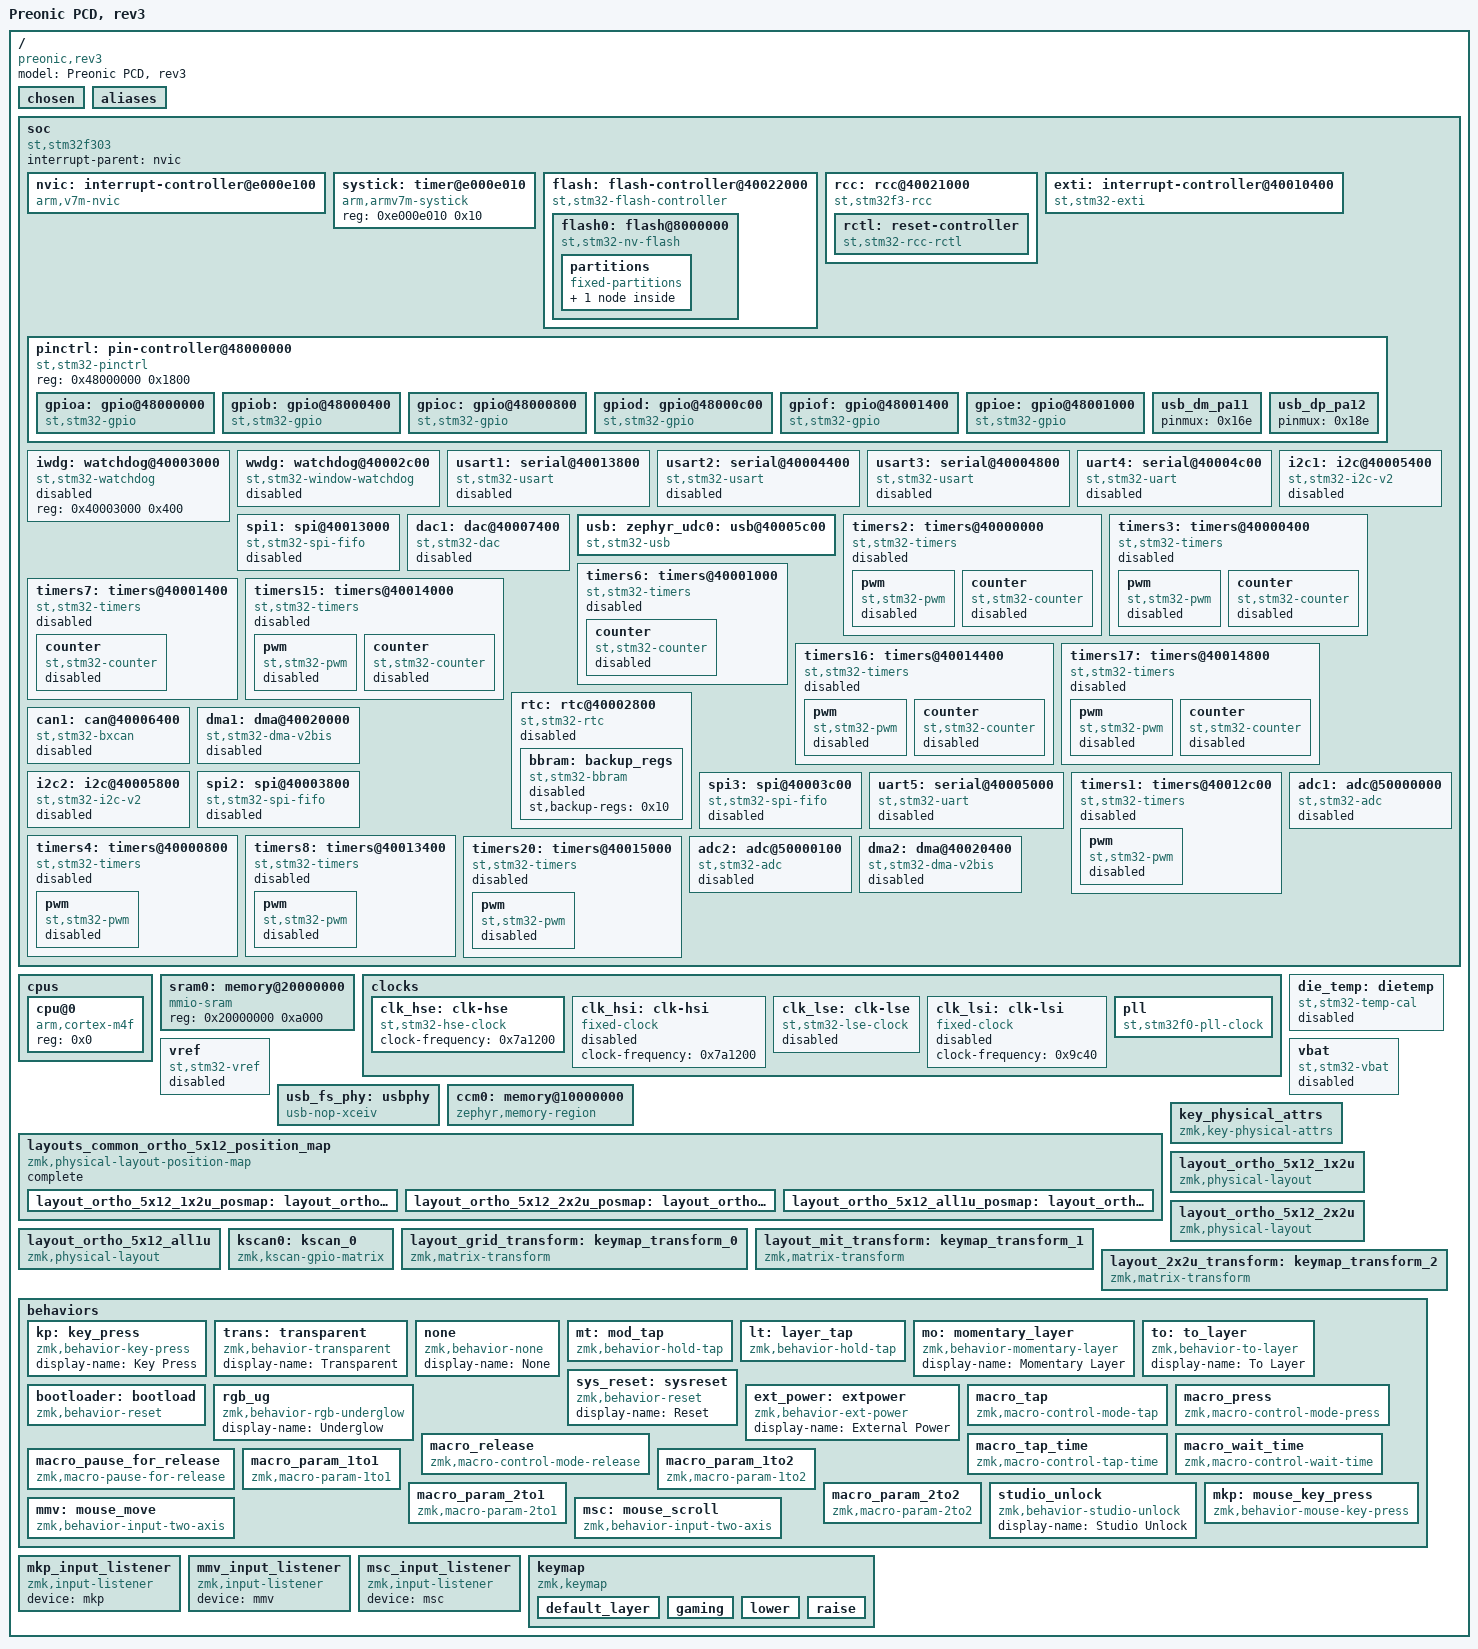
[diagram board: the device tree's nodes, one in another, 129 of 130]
/dts-v1/;

/ {
	#address-cells = < 0x1 >;
	#size-cells = < 0x1 >;
	model = "Preonic PCD, rev3";
	compatible = "preonic,rev3", "st,stm32f303";
	chosen {
		zephyr,flash-controller = &flash;
		zephyr,sram = &sram0;
		zephyr,flash = &flash0;
		zmk,kscan = &kscan0;
		zmk,physical-layout = &layout_ortho_5x12_all1u;
	};
	aliases {
	};
	soc {
		#address-cells = < 0x1 >;
		#size-cells = < 0x1 >;
		compatible = "st,stm32f303", "st,stm32f3", "simple-bus";
		interrupt-parent = < &nvic >;
		ranges;
		nvic: interrupt-controller@e000e100 {
			#address-cells = < 0x1 >;
			compatible = "arm,v7m-nvic";
			reg = < 0xe000e100 0xc00 >;
			interrupt-controller;
			#interrupt-cells = < 0x2 >;
			arm,num-irq-priority-bits = < 0x4 >;
			phandle = < 0x1 >;
		};
		systick: timer@e000e010 {
			compatible = "arm,armv7m-systick";
			reg = < 0xe000e010 0x10 >;
		};
		flash: flash-controller@40022000 {
			compatible = "st,stm32-flash-controller", "st,stm32f1-flash-controller";
			reg = < 0x40022000 0x400 >;
			interrupts = < 0x4 0x0 >;
			clocks = < &rcc 0x14 0x10 >;
			#address-cells = < 0x1 >;
			#size-cells = < 0x1 >;
			flash0: flash@8000000 {
				compatible = "st,stm32-nv-flash", "soc-nv-flash";
				write-block-size = < 0x2 >;
				erase-block-size = < 0x800 >;
				max-erase-time = < 0x28 >;
				reg = < 0x8000000 0x40000 >;
				partitions {
					compatible = "fixed-partitions";
					#address-cells = < 0x1 >;
					#size-cells = < 0x1 >;
					storage_partition: partition@3e800 {
						reg = < 0x3e800 0x1800 >;
					};
				};
			};
		};
		rcc: rcc@40021000 {
			compatible = "st,stm32f3-rcc";
			#clock-cells = < 0x2 >;
			reg = < 0x40021000 0x400 >;
			clocks = < &pll >;
			clock-frequency = < 0x44aa200 >;
			ahb-prescaler = < 0x1 >;
			apb1-prescaler = < 0x2 >;
			apb2-prescaler = < 0x1 >;
			phandle = < 0x2 >;
			rctl: reset-controller {
				compatible = "st,stm32-rcc-rctl";
				#reset-cells = < 0x1 >;
				phandle = < 0x4 >;
			};
		};
		exti: interrupt-controller@40010400 {
			compatible = "st,stm32-exti";
			interrupt-controller;
			#interrupt-cells = < 0x1 >;
			#address-cells = < 0x1 >;
			reg = < 0x40010400 0x400 >;
			num-lines = < 0x10 >;
			interrupts = < 0x6 0x0 >, < 0x7 0x0 >, < 0x8 0x0 >, < 0x9 0x0 >, < 0xa 0x0 >, < 0x17 0x0 >, < 0x28 0x0 >;
			interrupt-names = "line0", "line1", "line2", "line3", "line4", "line5-9", "line10-15";
			line-ranges = < 0x0 0x1 >, < 0x1 0x1 >, < 0x2 0x1 >, < 0x3 0x1 >, < 0x4 0x1 >, < 0x5 0x5 >, < 0xa 0x6 >;
		};
		pinctrl: pin-controller@48000000 {
			compatible = "st,stm32-pinctrl";
			#address-cells = < 0x1 >;
			#size-cells = < 0x1 >;
			reg = < 0x48000000 0x1800 >;
			gpioa: gpio@48000000 {
				compatible = "st,stm32-gpio";
				gpio-controller;
				#gpio-cells = < 0x2 >;
				reg = < 0x48000000 0x400 >;
				clocks = < &rcc 0x14 0x20000 >;
				phandle = < 0x11 >;
			};
			gpiob: gpio@48000400 {
				compatible = "st,stm32-gpio";
				gpio-controller;
				#gpio-cells = < 0x2 >;
				reg = < 0x48000400 0x400 >;
				clocks = < &rcc 0x14 0x40000 >;
				phandle = < 0x12 >;
			};
			gpioc: gpio@48000800 {
				compatible = "st,stm32-gpio";
				gpio-controller;
				#gpio-cells = < 0x2 >;
				reg = < 0x48000800 0x400 >;
				clocks = < &rcc 0x14 0x80000 >;
				phandle = < 0x13 >;
			};
			gpiod: gpio@48000c00 {
				compatible = "st,stm32-gpio";
				gpio-controller;
				#gpio-cells = < 0x2 >;
				reg = < 0x48000c00 0x400 >;
				clocks = < &rcc 0x14 0x100000 >;
			};
			gpiof: gpio@48001400 {
				compatible = "st,stm32-gpio";
				gpio-controller;
				#gpio-cells = < 0x2 >;
				reg = < 0x48001400 0x400 >;
				clocks = < &rcc 0x14 0x400000 >;
			};
			gpioe: gpio@48001000 {
				compatible = "st,stm32-gpio";
				gpio-controller;
				#gpio-cells = < 0x2 >;
				reg = < 0x48001000 0x400 >;
				clocks = < &rcc 0x14 0x200000 >;
			};
			usb_dm_pa11: usb_dm_pa11 {
				pinmux = < 0x16e >;
				phandle = < 0x6 >;
			};
			usb_dp_pa12: usb_dp_pa12 {
				pinmux = < 0x18e >;
				phandle = < 0x7 >;
			};
		};
		iwdg: watchdog@40003000 {
			compatible = "st,stm32-watchdog";
			reg = < 0x40003000 0x400 >;
			status = "disabled";
		};
		wwdg: watchdog@40002c00 {
			compatible = "st,stm32-window-watchdog";
			reg = < 0x40002c00 0x400 >;
			clocks = < &rcc 0x1c 0x800 >;
			interrupts = < 0x0 0x7 >;
			status = "disabled";
		};
		usart1: serial@40013800 {
			compatible = "st,stm32-usart", "st,stm32-uart";
			reg = < 0x40013800 0x400 >;
			clocks = < &rcc 0x18 0x4000 >;
			resets = < &rctl 0x18e >;
			interrupts = < 0x25 0x0 >;
			status = "disabled";
		};
		usart2: serial@40004400 {
			compatible = "st,stm32-usart", "st,stm32-uart";
			reg = < 0x40004400 0x400 >;
			clocks = < &rcc 0x1c 0x20000 >;
			resets = < &rctl 0x211 >;
			interrupts = < 0x26 0x0 >;
			status = "disabled";
		};
		usart3: serial@40004800 {
			compatible = "st,stm32-usart", "st,stm32-uart";
			reg = < 0x40004800 0x400 >;
			clocks = < &rcc 0x1c 0x40000 >;
			resets = < &rctl 0x212 >;
			interrupts = < 0x27 0x0 >;
			status = "disabled";
		};
		uart4: serial@40004c00 {
			compatible = "st,stm32-uart";
			reg = < 0x40004c00 0x400 >;
			clocks = < &rcc 0x1c 0x80000 >;
			resets = < &rctl 0x213 >;
			interrupts = < 0x34 0x0 >;
			status = "disabled";
		};
		i2c1: i2c@40005400 {
			compatible = "st,stm32-i2c-v2";
			clock-frequency = < 0x186a0 >;
			#address-cells = < 0x1 >;
			#size-cells = < 0x0 >;
			reg = < 0x40005400 0x400 >;
			clocks = < &rcc 0x1c 0x200000 >, < &rcc 0x4 0x12430 >;
			interrupts = < 0x1f 0x0 >, < 0x20 0x0 >;
			interrupt-names = "event", "error";
			status = "disabled";
		};
		spi1: spi@40013000 {
			compatible = "st,stm32-spi-fifo", "st,stm32-spi";
			#address-cells = < 0x1 >;
			#size-cells = < 0x0 >;
			reg = < 0x40013000 0x400 >;
			clocks = < &rcc 0x18 0x1000 >;
			interrupts = < 0x23 0x5 >;
			status = "disabled";
		};
		dac1: dac@40007400 {
			compatible = "st,stm32-dac";
			reg = < 0x40007400 0x400 >;
			clocks = < &rcc 0x1c 0x20000000 >;
			status = "disabled";
			#io-channel-cells = < 0x1 >;
		};
		usb: zephyr_udc0: usb@40005c00 {
			compatible = "st,stm32-usb";
			reg = < 0x40005c00 0x400 >;
			interrupts = < 0x4b 0x0 >;
			interrupt-names = "usb";
			num-bidir-endpoints = < 0x8 >;
			ram-size = < 0x200 >;
			phys = < &usb_fs_phy >;
			clocks = < &rcc 0x1c 0x800000 >;
			status = "okay";
			pinctrl-0 = < &usb_dm_pa11 &usb_dp_pa12 >;
			pinctrl-names = "default";
		};
		timers2: timers@40000000 {
			compatible = "st,stm32-timers";
			reg = < 0x40000000 0x400 >;
			clocks = < &rcc 0x1c 0x1 >;
			resets = < &rctl 0x200 >;
			interrupts = < 0x1c 0x0 >;
			interrupt-names = "global";
			st,prescaler = < 0x0 >;
			status = "disabled";
			pwm {
				compatible = "st,stm32-pwm";
				status = "disabled";
				#pwm-cells = < 0x3 >;
			};
			counter {
				compatible = "st,stm32-counter";
				status = "disabled";
			};
		};
		timers3: timers@40000400 {
			compatible = "st,stm32-timers";
			reg = < 0x40000400 0x400 >;
			clocks = < &rcc 0x1c 0x2 >;
			resets = < &rctl 0x201 >;
			interrupts = < 0x1d 0x0 >;
			interrupt-names = "global";
			st,prescaler = < 0x0 >;
			status = "disabled";
			pwm {
				compatible = "st,stm32-pwm";
				status = "disabled";
				#pwm-cells = < 0x3 >;
			};
			counter {
				compatible = "st,stm32-counter";
				status = "disabled";
			};
		};
		timers6: timers@40001000 {
			compatible = "st,stm32-timers";
			reg = < 0x40001000 0x400 >;
			clocks = < &rcc 0x1c 0x10 >;
			resets = < &rctl 0x204 >;
			interrupts = < 0x36 0x0 >;
			interrupt-names = "global";
			st,prescaler = < 0x0 >;
			status = "disabled";
			counter {
				compatible = "st,stm32-counter";
				status = "disabled";
			};
		};
		timers7: timers@40001400 {
			compatible = "st,stm32-timers";
			reg = < 0x40001400 0x400 >;
			clocks = < &rcc 0x1c 0x20 >;
			resets = < &rctl 0x205 >;
			interrupts = < 0x37 0x0 >;
			interrupt-names = "global";
			st,prescaler = < 0x0 >;
			status = "disabled";
			counter {
				compatible = "st,stm32-counter";
				status = "disabled";
			};
		};
		timers15: timers@40014000 {
			compatible = "st,stm32-timers";
			reg = < 0x40014000 0x400 >;
			clocks = < &rcc 0x18 0x10000 >;
			resets = < &rctl 0x190 >;
			interrupts = < 0x18 0x0 >;
			interrupt-names = "global";
			st,prescaler = < 0x0 >;
			status = "disabled";
			pwm {
				compatible = "st,stm32-pwm";
				status = "disabled";
				#pwm-cells = < 0x3 >;
			};
			counter {
				compatible = "st,stm32-counter";
				status = "disabled";
			};
		};
		timers16: timers@40014400 {
			compatible = "st,stm32-timers";
			reg = < 0x40014400 0x400 >;
			clocks = < &rcc 0x18 0x20000 >;
			resets = < &rctl 0x191 >;
			interrupts = < 0x19 0x0 >;
			interrupt-names = "global";
			st,prescaler = < 0x0 >;
			status = "disabled";
			pwm {
				compatible = "st,stm32-pwm";
				status = "disabled";
				#pwm-cells = < 0x3 >;
			};
			counter {
				compatible = "st,stm32-counter";
				status = "disabled";
			};
		};
		timers17: timers@40014800 {
			compatible = "st,stm32-timers";
			reg = < 0x40014800 0x400 >;
			clocks = < &rcc 0x18 0x40000 >;
			resets = < &rctl 0x192 >;
			interrupts = < 0x1a 0x0 >;
			interrupt-names = "global";
			st,prescaler = < 0x0 >;
			status = "disabled";
			pwm {
				compatible = "st,stm32-pwm";
				status = "disabled";
				#pwm-cells = < 0x3 >;
			};
			counter {
				compatible = "st,stm32-counter";
				status = "disabled";
			};
		};
		rtc: rtc@40002800 {
			compatible = "st,stm32-rtc";
			reg = < 0x40002800 0x400 >;
			clocks = < &rcc 0x1c 0x10000000 >;
			interrupts = < 0x29 0x0 >;
			prescaler = < 0x8000 >;
			status = "disabled";
			bbram: backup_regs {
				compatible = "st,stm32-bbram";
				st,backup-regs = < 0x10 >;
				status = "disabled";
			};
		};
		can1: can@40006400 {
			compatible = "st,stm32-bxcan";
			reg = < 0x40006400 0x400 >;
			interrupts = < 0x13 0x0 >, < 0x14 0x0 >, < 0x15 0x0 >, < 0x16 0x0 >;
			interrupt-names = "TX", "RX0", "RX1", "SCE";
			clocks = < &rcc 0x1c 0x2000000 >;
			status = "disabled";
			sample-point = < 0x36b >;
		};
		dma1: dma@40020000 {
			compatible = "st,stm32-dma-v2bis";
			#dma-cells = < 0x2 >;
			reg = < 0x40020000 0x400 >;
			clocks = < &rcc 0x14 0x1 >;
			interrupts = < 0xb 0x0 0xc 0x0 0xd 0x0 0xe 0x0 0xf 0x0 0x10 0x0 0x11 0x0 >;
			status = "disabled";
		};
		i2c2: i2c@40005800 {
			compatible = "st,stm32-i2c-v2";
			clock-frequency = < 0x186a0 >;
			#address-cells = < 0x1 >;
			#size-cells = < 0x0 >;
			reg = < 0x40005800 0x400 >;
			clocks = < &rcc 0x1c 0x400000 >, < &rcc 0x4 0x12530 >;
			interrupts = < 0x21 0x0 >, < 0x22 0x0 >;
			interrupt-names = "event", "error";
			status = "disabled";
		};
		spi2: spi@40003800 {
			compatible = "st,stm32-spi-fifo", "st,stm32-spi";
			#address-cells = < 0x1 >;
			#size-cells = < 0x0 >;
			reg = < 0x40003800 0x400 >;
			clocks = < &rcc 0x1c 0x4000 >;
			interrupts = < 0x24 0x5 >;
			status = "disabled";
		};
		spi3: spi@40003c00 {
			compatible = "st,stm32-spi-fifo", "st,stm32-spi";
			#address-cells = < 0x1 >;
			#size-cells = < 0x0 >;
			reg = < 0x40003c00 0x400 >;
			clocks = < &rcc 0x1c 0x8000 >;
			interrupts = < 0x33 0x5 >;
			status = "disabled";
		};
		uart5: serial@40005000 {
			compatible = "st,stm32-uart";
			reg = < 0x40005000 0x400 >;
			clocks = < &rcc 0x1c 0x100000 >;
			resets = < &rctl 0x214 >;
			interrupts = < 0x35 0x0 >;
			status = "disabled";
		};
		timers1: timers@40012c00 {
			compatible = "st,stm32-timers";
			reg = < 0x40012c00 0x400 >;
			clocks = < &rcc 0x18 0x800 >;
			resets = < &rctl 0x18b >;
			interrupts = < 0x18 0x0 >, < 0x19 0x0 >, < 0x1a 0x0 >, < 0x1b 0x0 >;
			interrupt-names = "brk", "up", "trgcom", "cc";
			st,prescaler = < 0x0 >;
			status = "disabled";
			pwm {
				compatible = "st,stm32-pwm";
				status = "disabled";
				#pwm-cells = < 0x3 >;
			};
		};
		timers4: timers@40000800 {
			compatible = "st,stm32-timers";
			reg = < 0x40000800 0x400 >;
			clocks = < &rcc 0x1c 0x4 >;
			resets = < &rctl 0x202 >;
			interrupts = < 0x1e 0x0 >;
			interrupt-names = "global";
			st,prescaler = < 0x0 >;
			status = "disabled";
			pwm {
				compatible = "st,stm32-pwm";
				status = "disabled";
				#pwm-cells = < 0x3 >;
			};
		};
		timers8: timers@40013400 {
			compatible = "st,stm32-timers";
			reg = < 0x40013400 0x400 >;
			clocks = < &rcc 0x18 0x2000 >;
			resets = < &rctl 0x18d >;
			interrupts = < 0x2b 0x0 >, < 0x2c 0x0 >, < 0x2d 0x0 >, < 0x2e 0x0 >;
			interrupt-names = "brk", "up", "trgcom", "cc";
			st,prescaler = < 0x0 >;
			status = "disabled";
			pwm {
				compatible = "st,stm32-pwm";
				status = "disabled";
				#pwm-cells = < 0x3 >;
			};
		};
		timers20: timers@40015000 {
			compatible = "st,stm32-timers";
			reg = < 0x40015000 0x400 >;
			clocks = < &rcc 0x18 0x100000 >;
			resets = < &rctl 0x194 >;
			interrupts = < 0x4d 0x0 >, < 0x4e 0x0 >, < 0x4f 0x0 >, < 0x50 0x0 >;
			interrupt-names = "brk", "up", "trgcom", "cc";
			st,prescaler = < 0x0 >;
			status = "disabled";
			pwm {
				compatible = "st,stm32-pwm";
				status = "disabled";
				#pwm-cells = < 0x3 >;
			};
		};
		adc1: adc@50000000 {
			compatible = "st,stm32-adc";
			reg = < 0x50000000 0x400 >;
			clocks = < &rcc 0x14 0x10000000 >;
			interrupts = < 0x12 0x0 >;
			status = "disabled";
			vref-mv = < 0xbb8 >;
			#io-channel-cells = < 0x1 >;
			resolutions = < 0x60630c 0x51630c 0x42630c 0x33630c >;
			sampling-times = < 0x2 0x3 0x5 0x8 0x14 0x3e 0xb6 0x25a >;
			st,adc-sequencer = < 0x1 >;
			phandle = < 0x9 >;
		};
		adc2: adc@50000100 {
			compatible = "st,stm32-adc";
			reg = < 0x50000100 0x4c >;
			clocks = < &rcc 0x14 0x10000000 >;
			interrupts = < 0x12 0x0 >;
			status = "disabled";
			vref-mv = < 0xbb8 >;
			#io-channel-cells = < 0x1 >;
			resolutions = < 0x60630c 0x51630c 0x42630c 0x33630c >;
			sampling-times = < 0x2 0x3 0x5 0x8 0x14 0x3e 0xb6 0x25a >;
			st,adc-sequencer = < 0x1 >;
		};
		dma2: dma@40020400 {
			compatible = "st,stm32-dma-v2bis";
			#dma-cells = < 0x2 >;
			reg = < 0x40020400 0x400 >;
			clocks = < &rcc 0x14 0x2 >;
			interrupts = < 0x38 0x0 0x39 0x0 0x3a 0x0 0x3b 0x0 0x3c 0x0 >;
			status = "disabled";
		};
	};
	cpus {
		#address-cells = < 0x1 >;
		#size-cells = < 0x0 >;
		cpu@0 {
			device_type = "cpu";
			compatible = "arm,cortex-m4f";
			reg = < 0x0 >;
		};
	};
	sram0: memory@20000000 {
		compatible = "mmio-sram";
		reg = < 0x20000000 0xa000 >;
	};
	clocks {
		clk_hse: clk-hse {
			#clock-cells = < 0x0 >;
			compatible = "st,stm32-hse-clock";
			status = "okay";
			clock-frequency = < 0x7a1200 >;
			phandle = < 0x8 >;
		};
		clk_hsi: clk-hsi {
			#clock-cells = < 0x0 >;
			compatible = "fixed-clock";
			clock-frequency = < 0x7a1200 >;
			status = "disabled";
		};
		clk_lse: clk-lse {
			#clock-cells = < 0x0 >;
			compatible = "st,stm32-lse-clock";
			clock-frequency = < 0x8000 >;
			driving-capability = < 0x0 >;
			status = "disabled";
		};
		clk_lsi: clk-lsi {
			#clock-cells = < 0x0 >;
			compatible = "fixed-clock";
			clock-frequency = < 0x9c40 >;
			status = "disabled";
		};
		pll: pll {
			#clock-cells = < 0x0 >;
			compatible = "st,stm32f0-pll-clock";
			status = "okay";
			prediv = < 0x1 >;
			mul = < 0x9 >;
			clocks = < &clk_hse >;
			phandle = < 0x3 >;
		};
	};
	die_temp: dietemp {
		compatible = "st,stm32-temp-cal";
		ts-cal1-addr = < 0x1ffff7b8 >;
		ts-cal2-addr = < 0x1ffff7c2 >;
		ts-cal1-temp = < 0x1e >;
		ts-cal2-temp = < 0x6e >;
		ts-cal-vrefanalog = < 0xce4 >;
		io-channels = < &adc1 0x10 >;
		status = "disabled";
	};
	vref: vref {
		compatible = "st,stm32-vref";
		vrefint-cal-addr = < 0x1ffff7ba >;
		vrefint-cal-mv = < 0xce4 >;
		io-channels = < &adc1 0x12 >;
		status = "disabled";
	};
	vbat: vbat {
		compatible = "st,stm32-vbat";
		ratio = < 0x2 >;
		io-channels = < &adc1 0x11 >;
		status = "disabled";
	};
	usb_fs_phy: usbphy {
		compatible = "usb-nop-xceiv";
		#phy-cells = < 0x0 >;
		phandle = < 0x5 >;
	};
	ccm0: memory@10000000 {
		compatible = "zephyr,memory-region", "st,stm32-ccm";
		reg = < 0x10000000 0x2000 >;
		zephyr,memory-region = "CCM";
	};
	layouts_common_ortho_5x12_position_map: layouts_common_ortho_5x12_position_map {
		compatible = "zmk,physical-layout-position-map";
		complete;
		layout_ortho_5x12_1x2u_posmap: layout_ortho_5x12_1x2u {
			physical-layout = < &layout_ortho_5x12_1x2u >;
			positions = < 0x0 0x1 0x2 0x3 0x4 0x5 0x6 0x7 0x8 0x9 0xa 0xb >, < 0xc 0xd 0xe 0xf 0x10 0x11 0x12 0x13 0x14 0x15 0x16 0x17 >, < 0x18 0x19 0x1a 0x1b 0x1c 0x1d 0x1e 0x1f 0x20 0x21 0x22 0x23 >, < 0x24 0x25 0x26 0x27 0x28 0x29 0x2a 0x2b 0x2c 0x2d 0x2e 0x2f >, < 0x30 0x31 0x32 0x33 0x34 0x35 0x3b 0x36 0x37 0x38 0x39 0x3a >;
		};
		layout_ortho_5x12_2x2u_posmap: layout_ortho_5x12_2x2u {
			physical-layout = < &layout_ortho_5x12_2x2u >;
			positions = < 0x0 0x1 0x2 0x3 0x4 0x5 0x6 0x7 0x8 0x9 0xa 0xb >, < 0xc 0xd 0xe 0xf 0x10 0x11 0x12 0x13 0x14 0x15 0x16 0x17 >, < 0x18 0x19 0x1a 0x1b 0x1c 0x1d 0x1e 0x1f 0x20 0x21 0x22 0x23 >, < 0x24 0x25 0x26 0x27 0x28 0x29 0x2a 0x2b 0x2c 0x2d 0x2e 0x2f >, < 0x30 0x31 0x32 0x33 0x34 0x3a 0x3b 0x35 0x36 0x37 0x38 0x39 >;
		};
		layout_ortho_5x12_all1u_posmap: layout_ortho_5x12_all1u {
			physical-layout = < &layout_ortho_5x12_all1u >;
			positions = < 0x0 0x1 0x2 0x3 0x4 0x5 0x6 0x7 0x8 0x9 0xa 0xb >, < 0xc 0xd 0xe 0xf 0x10 0x11 0x12 0x13 0x14 0x15 0x16 0x17 >, < 0x18 0x19 0x1a 0x1b 0x1c 0x1d 0x1e 0x1f 0x20 0x21 0x22 0x23 >, < 0x24 0x25 0x26 0x27 0x28 0x29 0x2a 0x2b 0x2c 0x2d 0x2e 0x2f >, < 0x30 0x31 0x32 0x33 0x34 0x35 0x36 0x37 0x38 0x39 0x3a 0x3b >;
		};
	};
	key_physical_attrs: key_physical_attrs {
		compatible = "zmk,key-physical-attrs";
		#key-cells = < 0x7 >;
		phandle = < 0xd >;
	};
	layout_ortho_5x12_1x2u: layout_ortho_5x12_1x2u {
		compatible = "zmk,physical-layout";
		display-name = "50% 1x2U Space";
		keys = < &key_physical_attrs 0x64 0x64 0x0 0x0 0x0 0x0 0x0 >, < &key_physical_attrs 0x64 0x64 0x64 0x0 0x0 0x0 0x0 >, < &key_physical_attrs 0x64 0x64 0xc8 0x0 0x0 0x0 0x0 >, < &key_physical_attrs 0x64 0x64 0x12c 0x0 0x0 0x0 0x0 >, < &key_physical_attrs 0x64 0x64 0x190 0x0 0x0 0x0 0x0 >, < &key_physical_attrs 0x64 0x64 0x1f4 0x0 0x0 0x0 0x0 >, < &key_physical_attrs 0x64 0x64 0x258 0x0 0x0 0x0 0x0 >, < &key_physical_attrs 0x64 0x64 0x2bc 0x0 0x0 0x0 0x0 >, < &key_physical_attrs 0x64 0x64 0x320 0x0 0x0 0x0 0x0 >, < &key_physical_attrs 0x64 0x64 0x384 0x0 0x0 0x0 0x0 >, < &key_physical_attrs 0x64 0x64 0x3e8 0x0 0x0 0x0 0x0 >, < &key_physical_attrs 0x64 0x64 0x44c 0x0 0x0 0x0 0x0 >, < &key_physical_attrs 0x64 0x64 0x0 0x64 0x0 0x0 0x0 >, < &key_physical_attrs 0x64 0x64 0x64 0x64 0x0 0x0 0x0 >, < &key_physical_attrs 0x64 0x64 0xc8 0x64 0x0 0x0 0x0 >, < &key_physical_attrs 0x64 0x64 0x12c 0x64 0x0 0x0 0x0 >, < &key_physical_attrs 0x64 0x64 0x190 0x64 0x0 0x0 0x0 >, < &key_physical_attrs 0x64 0x64 0x1f4 0x64 0x0 0x0 0x0 >, < &key_physical_attrs 0x64 0x64 0x258 0x64 0x0 0x0 0x0 >, < &key_physical_attrs 0x64 0x64 0x2bc 0x64 0x0 0x0 0x0 >, < &key_physical_attrs 0x64 0x64 0x320 0x64 0x0 0x0 0x0 >, < &key_physical_attrs 0x64 0x64 0x384 0x64 0x0 0x0 0x0 >, < &key_physical_attrs 0x64 0x64 0x3e8 0x64 0x0 0x0 0x0 >, < &key_physical_attrs 0x64 0x64 0x44c 0x64 0x0 0x0 0x0 >, < &key_physical_attrs 0x64 0x64 0x0 0xc8 0x0 0x0 0x0 >, < &key_physical_attrs 0x64 0x64 0x64 0xc8 0x0 0x0 0x0 >, < &key_physical_attrs 0x64 0x64 0xc8 0xc8 0x0 0x0 0x0 >, < &key_physical_attrs 0x64 0x64 0x12c 0xc8 0x0 0x0 0x0 >, < &key_physical_attrs 0x64 0x64 0x190 0xc8 0x0 0x0 0x0 >, < &key_physical_attrs 0x64 0x64 0x1f4 0xc8 0x0 0x0 0x0 >, < &key_physical_attrs 0x64 0x64 0x258 0xc8 0x0 0x0 0x0 >, < &key_physical_attrs 0x64 0x64 0x2bc 0xc8 0x0 0x0 0x0 >, < &key_physical_attrs 0x64 0x64 0x320 0xc8 0x0 0x0 0x0 >, < &key_physical_attrs 0x64 0x64 0x384 0xc8 0x0 0x0 0x0 >, < &key_physical_attrs 0x64 0x64 0x3e8 0xc8 0x0 0x0 0x0 >, < &key_physical_attrs 0x64 0x64 0x44c 0xc8 0x0 0x0 0x0 >, < &key_physical_attrs 0x64 0x64 0x0 0x12c 0x0 0x0 0x0 >, < &key_physical_attrs 0x64 0x64 0x64 0x12c 0x0 0x0 0x0 >, < &key_physical_attrs 0x64 0x64 0xc8 0x12c 0x0 0x0 0x0 >, < &key_physical_attrs 0x64 0x64 0x12c 0x12c 0x0 0x0 0x0 >, < &key_physical_attrs 0x64 0x64 0x190 0x12c 0x0 0x0 0x0 >, < &key_physical_attrs 0x64 0x64 0x1f4 0x12c 0x0 0x0 0x0 >, < &key_physical_attrs 0x64 0x64 0x258 0x12c 0x0 0x0 0x0 >, < &key_physical_attrs 0x64 0x64 0x2bc 0x12c 0x0 0x0 0x0 >, < &key_physical_attrs 0x64 0x64 0x320 0x12c 0x0 0x0 0x0 >, < &key_physical_attrs 0x64 0x64 0x384 0x12c 0x0 0x0 0x0 >, < &key_physical_attrs 0x64 0x64 0x3e8 0x12c 0x0 0x0 0x0 >, < &key_physical_attrs 0x64 0x64 0x44c 0x12c 0x0 0x0 0x0 >, < &key_physical_attrs 0x64 0x64 0x0 0x190 0x0 0x0 0x0 >, < &key_physical_attrs 0x64 0x64 0x64 0x190 0x0 0x0 0x0 >, < &key_physical_attrs 0x64 0x64 0xc8 0x190 0x0 0x0 0x0 >, < &key_physical_attrs 0x64 0x64 0x12c 0x190 0x0 0x0 0x0 >, < &key_physical_attrs 0x64 0x64 0x190 0x190 0x0 0x0 0x0 >, < &key_physical_attrs 0xc8 0x64 0x1f4 0x190 0x0 0x0 0x0 >, < &key_physical_attrs 0x64 0x64 0x2bc 0x190 0x0 0x0 0x0 >, < &key_physical_attrs 0x64 0x64 0x320 0x190 0x0 0x0 0x0 >, < &key_physical_attrs 0x64 0x64 0x384 0x190 0x0 0x0 0x0 >, < &key_physical_attrs 0x64 0x64 0x3e8 0x190 0x0 0x0 0x0 >, < &key_physical_attrs 0x64 0x64 0x44c 0x190 0x0 0x0 0x0 >;
		transform = < &layout_mit_transform >;
		phandle = < 0xa >;
	};
	layout_ortho_5x12_2x2u: layout_ortho_5x12_2x2u {
		compatible = "zmk,physical-layout";
		display-name = "50% 2x2U Space";
		keys = < &key_physical_attrs 0x64 0x64 0x0 0x0 0x0 0x0 0x0 >, < &key_physical_attrs 0x64 0x64 0x64 0x0 0x0 0x0 0x0 >, < &key_physical_attrs 0x64 0x64 0xc8 0x0 0x0 0x0 0x0 >, < &key_physical_attrs 0x64 0x64 0x12c 0x0 0x0 0x0 0x0 >, < &key_physical_attrs 0x64 0x64 0x190 0x0 0x0 0x0 0x0 >, < &key_physical_attrs 0x64 0x64 0x1f4 0x0 0x0 0x0 0x0 >, < &key_physical_attrs 0x64 0x64 0x258 0x0 0x0 0x0 0x0 >, < &key_physical_attrs 0x64 0x64 0x2bc 0x0 0x0 0x0 0x0 >, < &key_physical_attrs 0x64 0x64 0x320 0x0 0x0 0x0 0x0 >, < &key_physical_attrs 0x64 0x64 0x384 0x0 0x0 0x0 0x0 >, < &key_physical_attrs 0x64 0x64 0x3e8 0x0 0x0 0x0 0x0 >, < &key_physical_attrs 0x64 0x64 0x44c 0x0 0x0 0x0 0x0 >, < &key_physical_attrs 0x64 0x64 0x0 0x64 0x0 0x0 0x0 >, < &key_physical_attrs 0x64 0x64 0x64 0x64 0x0 0x0 0x0 >, < &key_physical_attrs 0x64 0x64 0xc8 0x64 0x0 0x0 0x0 >, < &key_physical_attrs 0x64 0x64 0x12c 0x64 0x0 0x0 0x0 >, < &key_physical_attrs 0x64 0x64 0x190 0x64 0x0 0x0 0x0 >, < &key_physical_attrs 0x64 0x64 0x1f4 0x64 0x0 0x0 0x0 >, < &key_physical_attrs 0x64 0x64 0x258 0x64 0x0 0x0 0x0 >, < &key_physical_attrs 0x64 0x64 0x2bc 0x64 0x0 0x0 0x0 >, < &key_physical_attrs 0x64 0x64 0x320 0x64 0x0 0x0 0x0 >, < &key_physical_attrs 0x64 0x64 0x384 0x64 0x0 0x0 0x0 >, < &key_physical_attrs 0x64 0x64 0x3e8 0x64 0x0 0x0 0x0 >, < &key_physical_attrs 0x64 0x64 0x44c 0x64 0x0 0x0 0x0 >, < &key_physical_attrs 0x64 0x64 0x0 0xc8 0x0 0x0 0x0 >, < &key_physical_attrs 0x64 0x64 0x64 0xc8 0x0 0x0 0x0 >, < &key_physical_attrs 0x64 0x64 0xc8 0xc8 0x0 0x0 0x0 >, < &key_physical_attrs 0x64 0x64 0x12c 0xc8 0x0 0x0 0x0 >, < &key_physical_attrs 0x64 0x64 0x190 0xc8 0x0 0x0 0x0 >, < &key_physical_attrs 0x64 0x64 0x1f4 0xc8 0x0 0x0 0x0 >, < &key_physical_attrs 0x64 0x64 0x258 0xc8 0x0 0x0 0x0 >, < &key_physical_attrs 0x64 0x64 0x2bc 0xc8 0x0 0x0 0x0 >, < &key_physical_attrs 0x64 0x64 0x320 0xc8 0x0 0x0 0x0 >, < &key_physical_attrs 0x64 0x64 0x384 0xc8 0x0 0x0 0x0 >, < &key_physical_attrs 0x64 0x64 0x3e8 0xc8 0x0 0x0 0x0 >, < &key_physical_attrs 0x64 0x64 0x44c 0xc8 0x0 0x0 0x0 >, < &key_physical_attrs 0x64 0x64 0x0 0x12c 0x0 0x0 0x0 >, < &key_physical_attrs 0x64 0x64 0x64 0x12c 0x0 0x0 0x0 >, < &key_physical_attrs 0x64 0x64 0xc8 0x12c 0x0 0x0 0x0 >, < &key_physical_attrs 0x64 0x64 0x12c 0x12c 0x0 0x0 0x0 >, < &key_physical_attrs 0x64 0x64 0x190 0x12c 0x0 0x0 0x0 >, < &key_physical_attrs 0x64 0x64 0x1f4 0x12c 0x0 0x0 0x0 >, < &key_physical_attrs 0x64 0x64 0x258 0x12c 0x0 0x0 0x0 >, < &key_physical_attrs 0x64 0x64 0x2bc 0x12c 0x0 0x0 0x0 >, < &key_physical_attrs 0x64 0x64 0x320 0x12c 0x0 0x0 0x0 >, < &key_physical_attrs 0x64 0x64 0x384 0x12c 0x0 0x0 0x0 >, < &key_physical_attrs 0x64 0x64 0x3e8 0x12c 0x0 0x0 0x0 >, < &key_physical_attrs 0x64 0x64 0x44c 0x12c 0x0 0x0 0x0 >, < &key_physical_attrs 0x64 0x64 0x0 0x190 0x0 0x0 0x0 >, < &key_physical_attrs 0x64 0x64 0x64 0x190 0x0 0x0 0x0 >, < &key_physical_attrs 0x64 0x64 0xc8 0x190 0x0 0x0 0x0 >, < &key_physical_attrs 0x64 0x64 0x12c 0x190 0x0 0x0 0x0 >, < &key_physical_attrs 0xc8 0x64 0x190 0x190 0x0 0x0 0x0 >, < &key_physical_attrs 0xc8 0x64 0x258 0x190 0x0 0x0 0x0 >, < &key_physical_attrs 0x64 0x64 0x320 0x190 0x0 0x0 0x0 >, < &key_physical_attrs 0x64 0x64 0x384 0x190 0x0 0x0 0x0 >, < &key_physical_attrs 0x64 0x64 0x3e8 0x190 0x0 0x0 0x0 >, < &key_physical_attrs 0x64 0x64 0x44c 0x190 0x0 0x0 0x0 >;
		transform = < &layout_2x2u_transform >;
		phandle = < 0xb >;
	};
	layout_ortho_5x12_all1u: layout_ortho_5x12_all1u {
		compatible = "zmk,physical-layout";
		display-name = "50% All 1U/Grid";
		keys = < &key_physical_attrs 0x64 0x64 0x0 0x0 0x0 0x0 0x0 >, < &key_physical_attrs 0x64 0x64 0x64 0x0 0x0 0x0 0x0 >, < &key_physical_attrs 0x64 0x64 0xc8 0x0 0x0 0x0 0x0 >, < &key_physical_attrs 0x64 0x64 0x12c 0x0 0x0 0x0 0x0 >, < &key_physical_attrs 0x64 0x64 0x190 0x0 0x0 0x0 0x0 >, < &key_physical_attrs 0x64 0x64 0x1f4 0x0 0x0 0x0 0x0 >, < &key_physical_attrs 0x64 0x64 0x258 0x0 0x0 0x0 0x0 >, < &key_physical_attrs 0x64 0x64 0x2bc 0x0 0x0 0x0 0x0 >, < &key_physical_attrs 0x64 0x64 0x320 0x0 0x0 0x0 0x0 >, < &key_physical_attrs 0x64 0x64 0x384 0x0 0x0 0x0 0x0 >, < &key_physical_attrs 0x64 0x64 0x3e8 0x0 0x0 0x0 0x0 >, < &key_physical_attrs 0x64 0x64 0x44c 0x0 0x0 0x0 0x0 >, < &key_physical_attrs 0x64 0x64 0x0 0x64 0x0 0x0 0x0 >, < &key_physical_attrs 0x64 0x64 0x64 0x64 0x0 0x0 0x0 >, < &key_physical_attrs 0x64 0x64 0xc8 0x64 0x0 0x0 0x0 >, < &key_physical_attrs 0x64 0x64 0x12c 0x64 0x0 0x0 0x0 >, < &key_physical_attrs 0x64 0x64 0x190 0x64 0x0 0x0 0x0 >, < &key_physical_attrs 0x64 0x64 0x1f4 0x64 0x0 0x0 0x0 >, < &key_physical_attrs 0x64 0x64 0x258 0x64 0x0 0x0 0x0 >, < &key_physical_attrs 0x64 0x64 0x2bc 0x64 0x0 0x0 0x0 >, < &key_physical_attrs 0x64 0x64 0x320 0x64 0x0 0x0 0x0 >, < &key_physical_attrs 0x64 0x64 0x384 0x64 0x0 0x0 0x0 >, < &key_physical_attrs 0x64 0x64 0x3e8 0x64 0x0 0x0 0x0 >, < &key_physical_attrs 0x64 0x64 0x44c 0x64 0x0 0x0 0x0 >, < &key_physical_attrs 0x64 0x64 0x0 0xc8 0x0 0x0 0x0 >, < &key_physical_attrs 0x64 0x64 0x64 0xc8 0x0 0x0 0x0 >, < &key_physical_attrs 0x64 0x64 0xc8 0xc8 0x0 0x0 0x0 >, < &key_physical_attrs 0x64 0x64 0x12c 0xc8 0x0 0x0 0x0 >, < &key_physical_attrs 0x64 0x64 0x190 0xc8 0x0 0x0 0x0 >, < &key_physical_attrs 0x64 0x64 0x1f4 0xc8 0x0 0x0 0x0 >, < &key_physical_attrs 0x64 0x64 0x258 0xc8 0x0 0x0 0x0 >, < &key_physical_attrs 0x64 0x64 0x2bc 0xc8 0x0 0x0 0x0 >, < &key_physical_attrs 0x64 0x64 0x320 0xc8 0x0 0x0 0x0 >, < &key_physical_attrs 0x64 0x64 0x384 0xc8 0x0 0x0 0x0 >, < &key_physical_attrs 0x64 0x64 0x3e8 0xc8 0x0 0x0 0x0 >, < &key_physical_attrs 0x64 0x64 0x44c 0xc8 0x0 0x0 0x0 >, < &key_physical_attrs 0x64 0x64 0x0 0x12c 0x0 0x0 0x0 >, < &key_physical_attrs 0x64 0x64 0x64 0x12c 0x0 0x0 0x0 >, < &key_physical_attrs 0x64 0x64 0xc8 0x12c 0x0 0x0 0x0 >, < &key_physical_attrs 0x64 0x64 0x12c 0x12c 0x0 0x0 0x0 >, < &key_physical_attrs 0x64 0x64 0x190 0x12c 0x0 0x0 0x0 >, < &key_physical_attrs 0x64 0x64 0x1f4 0x12c 0x0 0x0 0x0 >, < &key_physical_attrs 0x64 0x64 0x258 0x12c 0x0 0x0 0x0 >, < &key_physical_attrs 0x64 0x64 0x2bc 0x12c 0x0 0x0 0x0 >, < &key_physical_attrs 0x64 0x64 0x320 0x12c 0x0 0x0 0x0 >, < &key_physical_attrs 0x64 0x64 0x384 0x12c 0x0 0x0 0x0 >, < &key_physical_attrs 0x64 0x64 0x3e8 0x12c 0x0 0x0 0x0 >, < &key_physical_attrs 0x64 0x64 0x44c 0x12c 0x0 0x0 0x0 >, < &key_physical_attrs 0x64 0x64 0x0 0x190 0x0 0x0 0x0 >, < &key_physical_attrs 0x64 0x64 0x64 0x190 0x0 0x0 0x0 >, < &key_physical_attrs 0x64 0x64 0xc8 0x190 0x0 0x0 0x0 >, < &key_physical_attrs 0x64 0x64 0x12c 0x190 0x0 0x0 0x0 >, < &key_physical_attrs 0x64 0x64 0x190 0x190 0x0 0x0 0x0 >, < &key_physical_attrs 0x64 0x64 0x1f4 0x190 0x0 0x0 0x0 >, < &key_physical_attrs 0x64 0x64 0x258 0x190 0x0 0x0 0x0 >, < &key_physical_attrs 0x64 0x64 0x2bc 0x190 0x0 0x0 0x0 >, < &key_physical_attrs 0x64 0x64 0x320 0x190 0x0 0x0 0x0 >, < &key_physical_attrs 0x64 0x64 0x384 0x190 0x0 0x0 0x0 >, < &key_physical_attrs 0x64 0x64 0x3e8 0x190 0x0 0x0 0x0 >, < &key_physical_attrs 0x64 0x64 0x44c 0x190 0x0 0x0 0x0 >;
		transform = < &layout_grid_transform >;
		phandle = < 0xc >;
	};
	kscan0: kscan_0 {
		compatible = "zmk,kscan-gpio-matrix";
		diode-direction = "col2row";
		row-gpios = < &gpioa 0xa 0x20 >, < &gpioa 0x9 0x20 >, < &gpioa 0x8 0x20 >, < &gpiob 0xf 0x20 >, < &gpioc 0xd 0x20 >, < &gpioc 0xe 0x20 >, < &gpioc 0xf 0x20 >, < &gpioa 0x2 0x20 >, < &gpioa 0x3 0x20 >, < &gpioa 0x6 0x20 >;
		col-gpios = < &gpiob 0xb 0x0 >, < &gpiob 0xa 0x0 >, < &gpiob 0x2 0x0 >, < &gpiob 0x1 0x0 >, < &gpioa 0x7 0x0 >, < &gpiob 0x0 0x0 >;
	};
	layout_grid_transform: keymap_transform_0 {
		compatible = "zmk,matrix-transform";
		columns = < 0x6 >;
		rows = < 0xa >;
		map = < 0x0 0x1 0x2 0x3 0x4 0x5 0x400 0x401 0x402 0x403 0x404 0x405 0x100 0x101 0x102 0x103 0x104 0x105 0x500 0x501 0x502 0x503 0x504 0x505 0x200 0x201 0x202 0x203 0x204 0x205 0x600 0x601 0x602 0x603 0x604 0x605 0x300 0x301 0x302 0x303 0x304 0x305 0x700 0x701 0x702 0x703 0x704 0x705 0x800 0x801 0x802 0x903 0x904 0x905 0x900 0x901 0x902 0x803 0x804 0x805 >;
		phandle = < 0x10 >;
	};
	layout_mit_transform: keymap_transform_1 {
		compatible = "zmk,matrix-transform";
		columns = < 0x6 >;
		rows = < 0xa >;
		map = < 0x0 0x1 0x2 0x3 0x4 0x5 0x400 0x401 0x402 0x403 0x404 0x405 0x100 0x101 0x102 0x103 0x104 0x105 0x500 0x501 0x502 0x503 0x504 0x505 0x200 0x201 0x202 0x203 0x204 0x205 0x600 0x601 0x602 0x603 0x604 0x605 0x300 0x301 0x302 0x303 0x304 0x305 0x700 0x701 0x702 0x703 0x704 0x705 0x800 0x801 0x802 0x903 0x904 0x900 0x901 0x902 0x803 0x804 0x805 >;
		phandle = < 0xe >;
	};
	layout_2x2u_transform: keymap_transform_2 {
		compatible = "zmk,matrix-transform";
		columns = < 0x6 >;
		rows = < 0xa >;
		map = < 0x0 0x1 0x2 0x3 0x4 0x5 0x400 0x401 0x402 0x403 0x404 0x405 0x100 0x101 0x102 0x103 0x104 0x105 0x500 0x501 0x502 0x503 0x504 0x505 0x200 0x201 0x202 0x203 0x204 0x205 0x600 0x601 0x602 0x603 0x604 0x605 0x300 0x301 0x302 0x303 0x304 0x305 0x700 0x701 0x702 0x703 0x704 0x705 0x800 0x801 0x802 0x903 0x905 0x901 0x902 0x803 0x804 0x805 >;
		phandle = < 0xf >;
	};
	behaviors {
		kp: key_press {
			compatible = "zmk,behavior-key-press";
			#binding-cells = < 0x1 >;
			display-name = "Key Press";
			phandle = < 0x14 >;
		};
		trans: transparent {
			compatible = "zmk,behavior-transparent";
			#binding-cells = < 0x0 >;
			display-name = "Transparent";
			phandle = < 0x1c >;
		};
		none: none {
			compatible = "zmk,behavior-none";
			#binding-cells = < 0x0 >;
			display-name = "None";
			phandle = < 0x1b >;
		};
		mt: mod_tap {
			compatible = "zmk,behavior-hold-tap";
			#binding-cells = < 0x2 >;
			flavor = "tap-preferred";
			tapping-term-ms = < 0xc8 >;
			bindings = < &kp >, < &kp >;
			display-name = "Mod-Tap";
			phandle = < 0x19 >;
		};
		lt: layer_tap {
			compatible = "zmk,behavior-hold-tap";
			#binding-cells = < 0x2 >;
			flavor = "tap-preferred";
			tapping-term-ms = < 0xc8 >;
			bindings = < &mo >, < &kp >;
			display-name = "Layer-Tap";
			phandle = < 0x1a >;
		};
		mo: momentary_layer {
			compatible = "zmk,behavior-momentary-layer";
			#binding-cells = < 0x1 >;
			display-name = "Momentary Layer";
			phandle = < 0x15 >;
		};
		to: to_layer {
			compatible = "zmk,behavior-to-layer";
			#binding-cells = < 0x1 >;
			display-name = "To Layer";
			phandle = < 0x1d >;
		};
		sys_reset: sysreset {
			compatible = "zmk,behavior-reset";
			#binding-cells = < 0x0 >;
			display-name = "Reset";
		};
		bootloader: bootload {
			compatible = "zmk,behavior-reset";
			type = < 0x57 >;
			#binding-cells = < 0x0 >;
			display-name = "Bootloader";
			phandle = < 0x1e >;
		};
		rgb_ug: rgb_ug {
			compatible = "zmk,behavior-rgb-underglow";
			#binding-cells = < 0x2 >;
			display-name = "Underglow";
		};
		ext_power: extpower {
			compatible = "zmk,behavior-ext-power";
			#binding-cells = < 0x1 >;
			display-name = "External Power";
		};
		macro_tap: macro_tap {
			compatible = "zmk,macro-control-mode-tap";
			#binding-cells = < 0x0 >;
		};
		macro_press: macro_press {
			compatible = "zmk,macro-control-mode-press";
			#binding-cells = < 0x0 >;
		};
		macro_release: macro_release {
			compatible = "zmk,macro-control-mode-release";
			#binding-cells = < 0x0 >;
		};
		macro_tap_time: macro_tap_time {
			compatible = "zmk,macro-control-tap-time";
			#binding-cells = < 0x1 >;
		};
		macro_wait_time: macro_wait_time {
			compatible = "zmk,macro-control-wait-time";
			#binding-cells = < 0x1 >;
		};
		macro_pause_for_release: macro_pause_for_release {
			compatible = "zmk,macro-pause-for-release";
			#binding-cells = < 0x0 >;
		};
		macro_param_1to1: macro_param_1to1 {
			compatible = "zmk,macro-param-1to1";
			#binding-cells = < 0x0 >;
		};
		macro_param_1to2: macro_param_1to2 {
			compatible = "zmk,macro-param-1to2";
			#binding-cells = < 0x0 >;
		};
		macro_param_2to1: macro_param_2to1 {
			compatible = "zmk,macro-param-2to1";
			#binding-cells = < 0x0 >;
		};
		macro_param_2to2: macro_param_2to2 {
			compatible = "zmk,macro-param-2to2";
			#binding-cells = < 0x0 >;
		};
		studio_unlock: studio_unlock {
			compatible = "zmk,behavior-studio-unlock";
			#binding-cells = < 0x0 >;
			display-name = "Studio Unlock";
		};
		mkp: mouse_key_press {
			compatible = "zmk,behavior-mouse-key-press";
			#binding-cells = < 0x1 >;
			phandle = < 0x16 >;
		};
		mmv: mouse_move {
			compatible = "zmk,behavior-input-two-axis";
			#binding-cells = < 0x1 >;
			x-input-code = < 0x0 >;
			y-input-code = < 0x1 >;
			time-to-max-speed-ms = < 0x12c >;
			acceleration-exponent = < 0x1 >;
			phandle = < 0x17 >;
		};
		msc: mouse_scroll {
			compatible = "zmk,behavior-input-two-axis";
			#binding-cells = < 0x1 >;
			x-input-code = < 0x6 >;
			y-input-code = < 0x8 >;
			time-to-max-speed-ms = < 0x12c >;
			acceleration-exponent = < 0x0 >;
			phandle = < 0x18 >;
		};
	};
	mkp_input_listener: mkp_input_listener {
		compatible = "zmk,input-listener";
		device = < &mkp >;
	};
	mmv_input_listener: mmv_input_listener {
		compatible = "zmk,input-listener";
		device = < &mmv >;
	};
	msc_input_listener: msc_input_listener {
		compatible = "zmk,input-listener";
		device = < &msc >;
	};
	keymap {
		compatible = "zmk,keymap";
		default_layer {
			bindings = < &kp 0x70035 &kp 0x7001e &kp 0x7001f &kp 0x70020 &kp 0x70021 &kp 0x70022 &kp 0x70023 &kp 0x70024 &kp 0x70025 &kp 0x70026 &kp 0x70027 &kp 0x7002a &kp 0x7002b &kp 0x70014 &kp 0x7001a &kp 0x70008 &kp 0x70015 &kp 0x70017 &kp 0x7001c &kp 0x70018 &kp 0x7000c &kp 0x70012 &kp 0x70013 &mt 0x700e7 0x7004c &mt 0x700e2 0x70029 &kp 0x70004 &kp 0x70016 &mt 0x700e0 0x70007 &mt 0x700e3 0x70009 &kp 0x7000a &kp 0x7000b &mt 0x700e3 0x7000d &mt 0x700e0 0x7000e &kp 0x7000f &kp 0x70033 &mt 0x700e2 0x70034 &kp 0x700e1 &kp 0x7001d &kp 0x7001b &kp 0x70006 &kp 0x70019 &kp 0x70005 &kp 0x70011 &kp 0x70010 &kp 0x70036 &kp 0x70037 &kp 0x70038 &mt 0x700e5 0x70028 &kp 0x700e0 &kp 0x700e0 &kp 0x700e2 &kp 0x700e3 &lt 0x2 0x7002b &lt 0x3 0x7002c &lt 0x3 0x7002c &lt 0x3 0x7002c &kp 0x70050 &kp 0x70051 &kp 0x70052 &kp 0x7004f >;
		};
		gaming {
			bindings = < &kp 0x70035 &kp 0x7001e &kp 0x7001f &kp 0x70020 &kp 0x70021 &kp 0x70022 &kp 0x70023 &kp 0x70024 &kp 0x70025 &kp 0x70026 &kp 0x70027 &kp 0x7002a &kp 0x7002b &kp 0x70014 &kp 0x7001a &kp 0x70008 &kp 0x70015 &kp 0x70017 &kp 0x7001c &kp 0x70018 &kp 0x7000c &kp 0x70012 &kp 0x70013 &kp 0x807002b &kp 0x70029 &kp 0x70004 &kp 0x70016 &kp 0x70007 &kp 0x70009 &kp 0x7000a &kp 0x7000b &kp 0x7000d &kp 0x7000e &kp 0x7000f &kp 0x70033 &kp 0x70034 &kp 0x700e1 &kp 0x7001d &kp 0x7001b &kp 0x70006 &kp 0x70019 &kp 0x70005 &kp 0x70011 &kp 0x70010 &kp 0x70036 &kp 0x70037 &kp 0x70038 &kp 0x70028 &kp 0x700e0 &kp 0x700e0 &kp 0x700e2 &kp 0x700e3 &kp 0x7002c &kp 0x7002c &kp 0x7002c &mo 0x3 &kp 0x70050 &kp 0x70051 &kp 0x70052 &kp 0x7004f >;
		};
		lower {
			bindings = < &kp 0x2070035 &kp 0x7003a &kp 0x7003b &kp 0x7003c &kp 0x7003d &kp 0x7003e &kp 0x7003f &kp 0x70040 &kp 0x70041 &kp 0x70042 &kp 0x70043 &kp 0x70044 &kp 0x2070035 &kp 0x207001e &kp 0x207001f &kp 0x2070020 &kp 0x2070021 &kp 0x2070022 &kp 0x70037 &kp 0x70024 &kp 0x70025 &kp 0x70026 &none &kp 0x70045 &kp 0x7004c &kp 0x2070023 &kp 0x2070024 &kp 0x2070025 &kp 0x2070026 &kp 0x2070027 &kp 0x7002d &kp 0x70021 &kp 0x70022 &kp 0x70023 &none &kp 0x70028 &trans &kp 0x70031 &kp 0x7002f &kp 0x70030 &kp 0x207002f &kp 0x2070030 &kp 0x70045 &kp 0x7001e &kp 0x7001f &kp 0x70020 &none &kp 0x70027 &trans &trans &trans &trans &trans &trans &trans &kp 0x70027 &kp 0xc00b5 &kp 0xc00e9 &kp 0xc00e9 &kp 0xc00b0 >;
		};
		raise {
			bindings = < &none &to 0x0 &to 0x1 &none &none &none &none &none &none &none &none &bootloader &none &none &none &none &none &none &none &none &kp 0x307002b &kp 0x107002b &none &none &none &none &none &none &none &none &kp 0x70050 &kp 0x70051 &kp 0x70052 &kp 0x7004f &none &none &none &none &none &none &none &none &none &kp 0x7004e &kp 0x7004b &none &none &none &none &none &none &none &none &none &none &none &kp 0xc00b5 &kp 0xc00ea &kp 0xc00e9 &kp 0xc00b0 >;
		};
	};
};
